# RegMap_Demo register map
Vendor: Teradyne; Series: DEMO; File version: 100
Generic CMSIS-SVD placeholder with clustered register maps for demo purposes.
CPU: other r0p0, little endian, no MPU, no FPU, 4 interrupt priority bits
Registers are 32-bit, read-write, reset 0x0 unless marked. A register's access mark holds for its fields unless they carry their own. Offsets are from the block's base; lines under a group give offsets from that group; [hi:lo] are bit positions; {n}, {i} and the like mark numbered series; 'fields as' and 'values as' point back to an identical list; <NAME> marks a mode.

## Memory map
0x40000000 PERIPH_A size 0x1000 — Demo Peripheral A
0x40001000 PERIPH_B blocks up to offset 0x1004 — Demo Peripheral B - Bus control unit
0x40002000 PERIPH_C blocks up to offset 0x1004 — Demo Peripheral C - Communication bus control unit

## PERIPH_A — Demo Peripheral A
Base 0x40000000
0x00 SUBBLOCK_A group — Configuration sub-block A
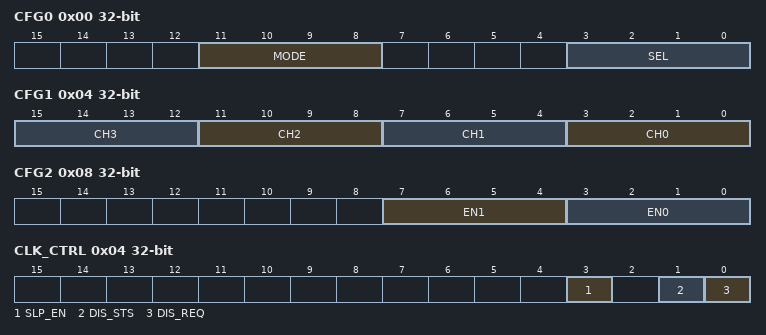
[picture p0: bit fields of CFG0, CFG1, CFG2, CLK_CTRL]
  0x00 CFG0 — Configuration register 0
    [11:8] MODE — Mode control field
    [3:0] SEL — Selection field
  0x04 CFG1 — Configuration register 1
    [4n+3:4n] CH{n} (n=0..3) — Channel {n} assignment
  0x08 CFG2 — Configuration register 2
    [7:4] EN1 — Enable block 1
    [3:0] EN0 — Enable block 0
0x04 CLK_CTRL access per field — Clock control register
  [3] SLP_EN rw — Sleep mode enable control
  [1] DIS_STS ro — Module disable status bit
  [0] DIS_REQ rw — Module disable request bit
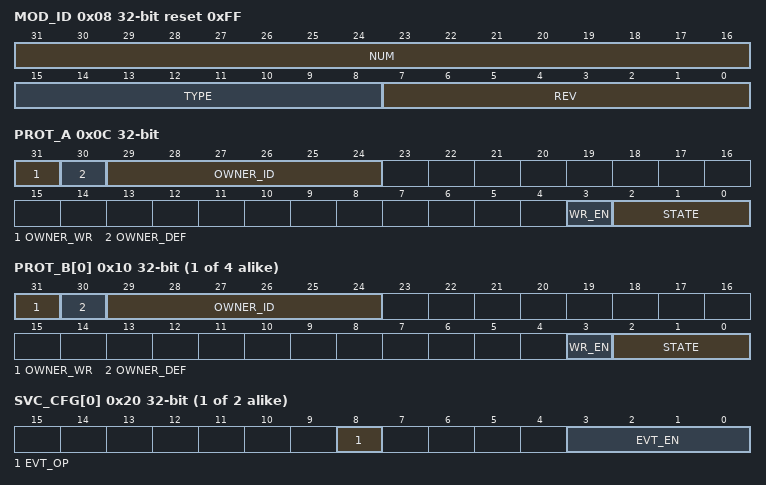
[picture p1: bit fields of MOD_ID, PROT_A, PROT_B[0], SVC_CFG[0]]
0x08 MOD_ID ro reset 0xFF — Module identification register
  [31:16] NUM — Module identification number
  [15:8] TYPE — Module type marker
  [7:0] REV — Module revision number
0x0C PROT_A access per field — Protection register A
  [31] OWNER_WR wo — Owner write enable
    0=Disable0 (Owner fields are not updated); 1=Enable1 (Owner fields are updated by the write)
  [30] OWNER_DEF rw — Enable owner definition
    0=Undefined0 (Any master can act as owner); 1=Defined1 (Owner fields define the owner)
  [29:24] OWNER_ID rw — Owner TAG ID definition
  [3] WR_EN wo — State write enable
    0=Disable0 (STATE field is not updated); 1=Enable1 (STATE field is updated by the write)
  [2:0] STATE rw — Protection state
{0x10+4i} PROT_B[{i}] (i=0..3) access per field — Protection register B array
  fields as PROT_A
{0x20+4i} SVC_CFG[{i}] (i=0..1) — Service request configuration register
  [8] EVT_OP — Event operation mode
  [3:0] EVT_EN — Event enable
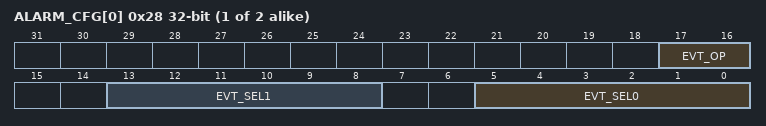
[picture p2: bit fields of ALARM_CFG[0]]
{0x28+4i} ALARM_CFG[{i}] (i=0..1) — Alarm configuration register
  [17:16] EVT_OP — Event operation mode
  [13:8] EVT_SEL1 — Event source select 1
  [5:0] EVT_SEL0 — Event source select 0
0x30 ALARM_SET wo
  [7:0] TRIG — Software alarm trigger

## PERIPH_B — Demo Peripheral B - Bus control unit
Base 0x40001000
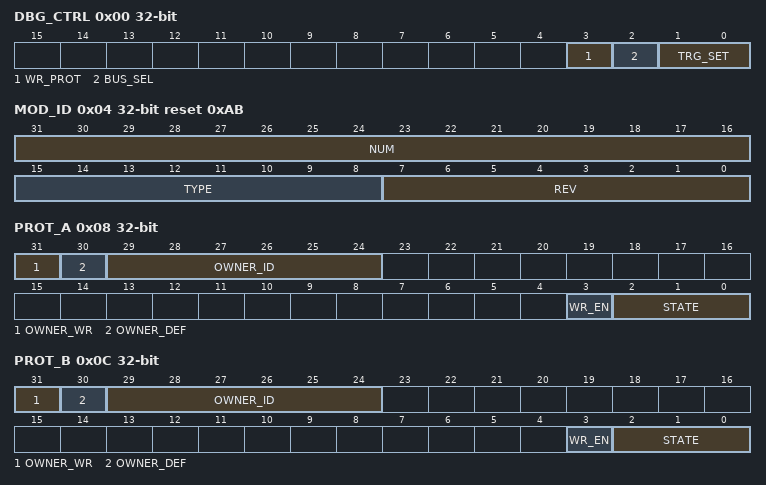
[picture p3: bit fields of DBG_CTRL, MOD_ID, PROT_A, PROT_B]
0x00 DBG_CTRL access per field — Debug control and status register
  [3] WR_PROT wo — Write protection for trigger fields
  [2] BUS_SEL rw — Bus select
  [1:0] TRG_SET rw — Trigger set select
0x04 MOD_ID ro reset 0xAB — Module identification register
  [31:16] NUM — Module identification number
  [15:8] TYPE — Module type marker
  [7:0] REV — Module revision number
0x08 PROT_A access per field — Protection register A
  fields as PERIPH_A.PROT_A
0x0C PROT_B access per field — Protection register B
  fields as PERIPH_A.PROT_A
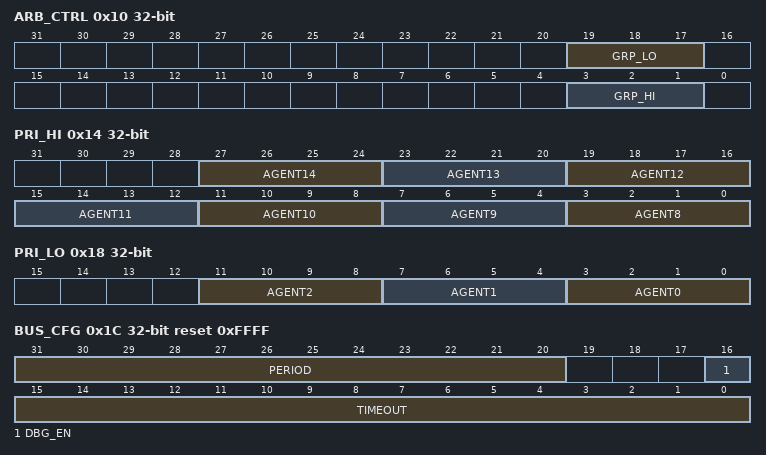
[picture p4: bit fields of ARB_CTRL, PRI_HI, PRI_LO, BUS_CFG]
0x10 ARB_CTRL — Arbitration control register
  [19:17] GRP_LO — Low priority group round share
  [3:1] GRP_HI — High priority group round share
0x14 PRI_HI — Priority register high
  [4n-29:4n-32] AGENT{n} (n=8..14) — Agent {n} priority
0x18 PRI_LO — Priority register low
  [11:8] AGENT2 — Agent 2 priority
  [7:4] AGENT1 — Agent 1 priority
  [3:0] AGENT0 — Agent 0 priority
0x1C BUS_CFG reset 0xFFFF — Bus configuration register
  [31:20] PERIOD — Starvation period control
  [16] DBG_EN — Debug trace enable
  [15:0] TIMEOUT — Timeout value in wait state cycles
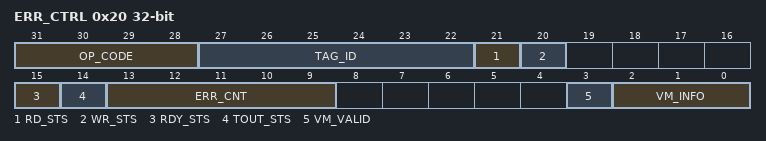
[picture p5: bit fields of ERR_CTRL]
0x20 ERR_CTRL — Error control capture register
  [31:28] OP_CODE — Operation code at error
  [27:22] TAG_ID — Master agent TAG ID at error
  [21] RD_STS — Read transaction status at error
  [20] WR_STS — Write transaction status at error
  [15] RDY_STS — Ready signal state
  [14] TOUT_STS — Timeout signal state
  [13:9] ERR_CNT — Error counter
  [3] VM_VALID — VM information valid signal
  [2:0] VM_INFO — Virtual machine information at error
0x24 ERR_ADDR — Error address capture register
  [31:0] ADDR — Captured bus address at error

## PERIPH_C — Demo Peripheral C - Communication bus control unit
Base 0x40002000
Registers as PERIPH_B; these are added or differ:
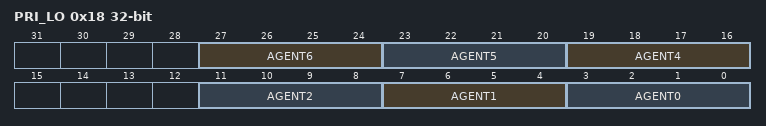
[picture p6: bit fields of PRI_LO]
0x18 PRI_LO — Priority register low
  [27:24] AGENT6 — Agent 6 priority
  [23:20] AGENT5 — Agent 5 priority
  [19:16] AGENT4 — Agent 4 priority
  [11:8] AGENT2 — Agent 2 priority
  [7:4] AGENT1 — Agent 1 priority
  [3:0] AGENT0 — Agent 0 priority
